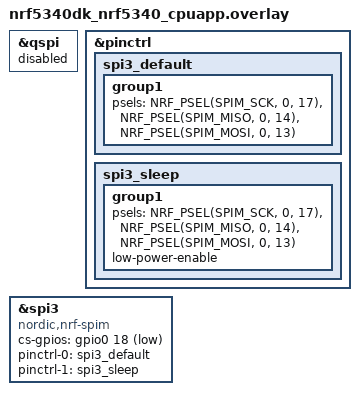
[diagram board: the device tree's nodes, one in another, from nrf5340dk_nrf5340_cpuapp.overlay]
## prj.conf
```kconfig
# nothing here
CONFIG_SPI=y
CONFIG_GPIO=y
```

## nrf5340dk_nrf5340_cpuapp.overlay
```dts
// To get started, press Ctrl+Space to bring up the completion menu and view the available nodes.

// You can also use the buttons in the sidebar to perform actions on nodes.
// Actions currently available include:

// * Enabling / disabling the node
// * Adding the bus to a bus
// * Removing the node
// * Connecting ADC channels

// For more help, browse the DeviceTree documentation at https://docs.zephyrproject.org/latest/guides/dts/index.html
// You can also visit the nRF DeviceTree extension documentation at https://nrfconnect.github.io/vscode-nrf-connect/devicetree/nrfdevicetree.html
&qspi {
	status = "disabled";
};

&pinctrl {
    spi3_default: spi3_default {
        group1 {
            psels = <NRF_PSEL(SPIM_SCK, 0, 17)>,
                    <NRF_PSEL(SPIM_MISO, 0, 14)>,
                    <NRF_PSEL(SPIM_MOSI, 0, 13)>;
        };
    };

    spi3_sleep: spi3_sleep {
        group1 {
            psels = <NRF_PSEL(SPIM_SCK, 0, 17)>,
                <NRF_PSEL(SPIM_MISO, 0, 14)>,
                <NRF_PSEL(SPIM_MOSI, 0, 13)>;
            low-power-enable;
        };
    };
};

&spi3 {
	compatible = "nordic,nrf-spim";
	status = "okay";
	cs-gpios = <&gpio0 18 GPIO_ACTIVE_LOW>;
	pinctrl-0 = <&spi3_default>;
	pinctrl-1 = <&spi3_sleep>;
	pinctrl-names = "default", "sleep";
};
```

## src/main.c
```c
/*
 * Copyright (c) 2012-2014 Wind River Systems, Inc.
 *
 * SPDX-License-Identifier: Apache-2.0
 */

#include <zephyr/kernel.h>
#include <zephyr/device.h>
#include <zephyr/devicetree.h>
#include <stdio.h>
#include <string.h>
#include <zephyr/drivers/spi.h>

const struct device *dev = DEVICE_DT_GET(DT_NODELABEL(spi3));

static struct spi_config spi_cfg = {
	.operation = SPI_WORD_SET(8) | SPI_OP_MODE_MASTER | SPI_TRANSFER_MSB,
	.frequency = 1000000,
	.slave = 0, 
};

void serial_flash_spi_test( struct spi_cs_control *cs)
{
	int err;
	static uint8_t tx_buffer[1];
	static uint8_t rx_buffer[4];	

	const struct spi_buf tx_buf = {
		.buf = tx_buffer,
		.len = sizeof(tx_buffer)
	};
	const struct spi_buf_set tx = {
		.buffers = &tx_buf,
		.count = 1
	};

	struct spi_buf rx_buf = {
		.buf = rx_buffer,
		.len = sizeof(rx_buffer),
	};
	const struct spi_buf_set rx = {
		.buffers = &rx_buf,
		.count = 1	
	};

	spi_cfg.cs = cs;

	/* 1 byte manufacturer ID & 2 bytes device ID */
	tx_buffer[0] = 0x9F; //RDID(Read identification)

	err = spi_transceive(dev, &spi_cfg, &tx, &rx);
	if (err) {
		printk("SPI error: %d\n", err);
	} else {
		/* Connect MISO to MOSI for loopback */
		printk("TX sent: %x\n", tx_buffer[0]);
		printk("RX recv: %x %x %x %x\n", rx_buffer[0], rx_buffer[1], rx_buffer[2], rx_buffer[3]);
	}	
}

void main(void)
{
	struct spi_cs_control cs_ctrl = (struct spi_cs_control){
		.gpio = GPIO_DT_SPEC_GET(DT_NODELABEL(spi3), cs_gpios),
		.delay = 0u,
	};

	printk("HW SPI test with SPI3\n");

	if (!device_is_ready(dev)) {
    	return;
	}

	while(1)
	{
		serial_flash_spi_test(&cs_ctrl);
		k_sleep(K_MSEC(1000));		
	}
}
```
